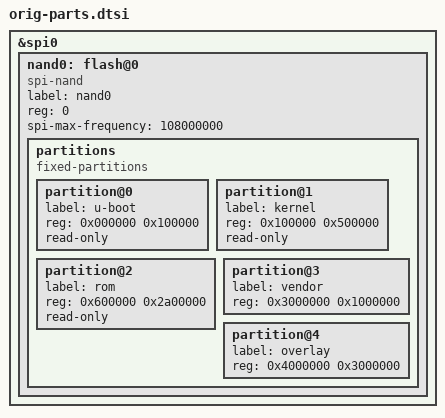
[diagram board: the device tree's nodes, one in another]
&spi0 {
	status = "okay";

	nand0: flash@0 {
		#address-cells = <1>;
		#size-cells = <1>;
		compatible = "spi-nand";
		label = "nand0";
		reg = <0>;
		spi-max-frequency = <108000000>;

		partitions {
			compatible = "fixed-partitions";
			#address-cells = <1>;
			#size-cells = <1>;

			partition@0 {
				label = "u-boot";
				reg = <0x000000 0x100000>;
				read-only;
			};

			partition@1 {
				label = "kernel";
				reg = <0x100000 0x500000>;
				read-only;
			};

			partition@2 {
				label = "rom";
				reg = <0x600000 0x2a00000>;
				read-only;
			};

			partition@3 {
				label = "vendor";
				reg = <0x3000000 0x1000000>;
			};

			partition@4 {
				label = "overlay";
				reg = <0x4000000 0x3000000>;
			};
		};
	};
};
